# nrf5340_application register map
Vendor: Nordic Semiconductor; Series: nrf53; File version: 1
CPU: CM33 r0p4, little endian, MPU, FPU, 3 interrupt priority bits, 69 interrupts
Registers are 32-bit, read-write, reset 0x0 unless marked. A register's access mark holds for its fields unless they carry their own. Offsets are from the block's base; [hi:lo] are bit positions; {n}, {i} and the like mark numbered series.

## CC_CHACHA_S — CRYPTOCELL CHACHA engine
Base 0x50845000; alternate view of CC_AES_S
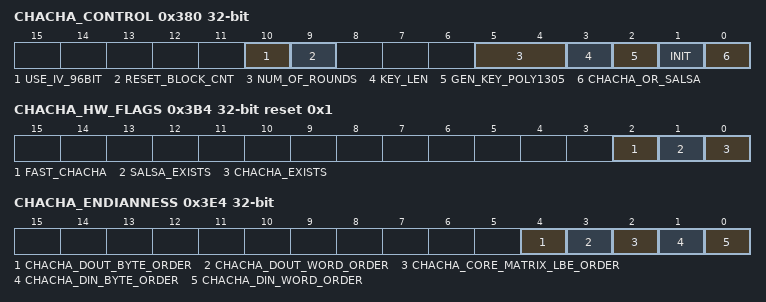
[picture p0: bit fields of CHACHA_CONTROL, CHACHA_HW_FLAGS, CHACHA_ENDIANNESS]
0x380 CHACHA_CONTROL — Control the CHACHA engine behavior.
  [10] USE_IV_96BIT — Use 96 bits Initialization Vector (IV)
    0=Disable (Use default size IV of 64 bit); 1=Enable (The IV is 96 bits)
  [9] RESET_BLOCK_CNT — Reset block counter for new messages
    0=Disable (Use current block counter value); 1=Enable (Reset block counter value to zero)
  [5:4] NUM_OF_ROUNDS — Set number of permutation rounds, default value is 20.
    0=Default (Use 20 rounds of rotation (default)); 1=12Rounds (Use 12 rounds of rotation); 2=8Rounds (Use 8 rounds of rotation)
  [3] KEY_LEN — Key length selection.
    0=256Bits (Use 256 bits key length); 1=128Bits (Use 128 bits key length)
  [2] GEN_KEY_POLY1305 — Generate the key to use in Poly1305 message authentication code calculation.
    0=Disable (Do not generate Poly1305 key); 1=Enable (Generate Poly1305 key)
  [1] INIT — Perform initialization for a new message
    0=Disable (Message already initialized); 1=Enable (Initialize new message)
  [0] CHACHA_OR_SALSA — Run engine in ChaCha or Salsa mode
    0=ChaCha (Run engine in ChaCha mode); 1=Salsa (Run engine in Salsa mode)
0x384 CHACHA_VERSION ro reset 0x1 — CHACHA engine HW version
{0x388+4i} CHACHA_KEY[{i}] (i=0..7) wo — Description collection: CHACHA key value to use. The initial CHACHA_KEY[0] register holds the least significant bits [31:0] of the key value.
  [31:0] VALUE — CHACHA key value.
{0x3A8+4i} CHACHA_IV[{i}] (i=0..1) — Description collection: CHACHA Initialization Vector (IV) to use. The IV is also known as the nonce.
  [31:0] VALUE — CHACHA IV value.
0x3B0 CHACHA_BUSY ro — Status register for CHACHA engine activity.
  [0] STATUS — CHACHA engine status.
    0=Idle (CHACHA engine is idle); 1=Busy (CHACHA engine is busy)
0x3B4 CHACHA_HW_FLAGS ro reset 0x1 — Hardware configuration of the CHACHA engine. Reset value holds the supported features.
  [2] FAST_CHACHA — If this flag is set, the next matrix calculated when the current one is written to data output path.
  [1] SALSA_EXISTS — If this flag is set, the engine include Salsa support
  [0] CHACHA_EXISTS — If this flag is set, the engine include ChaCha support
0x3B8 CHACHA_BLOCK_CNT_LSB — Store the LSB value of the block counter, in order to support suspend/resume of operation
  [31:0] VALUE — This register holds the ChaCha block counter bits [31:0] and must be read and written during respectively suspend and resume operations.
0x3BC CHACHA_BLOCK_CNT_MSB — Store the MSB value of the block counter, in order to support suspend/resume of operation
  [31:0] VALUE — This register holds the ChaCha block counter bits [63:32] and must be read and written during respectively suspend and resume operations.
0x3C0 CHACHA_SW_RESET wo — Reset the CHACHA engine.
  [0] RESET — Writing any value to this address resets the CHACHA engine. The reset takes 4 CPU clock cycles to complete.
    1=Enable (Reset CHACHA engine.)
{0x3C4+4i} CHACHA_POLY1305_KEY[{i}] (i=0..7) ro — Description collection: The auto-generated key to use in Poly1305 MAC calculation. The initial CHACHA_POLY1305_KEY[0] register holds the least significant bits [31:0] of the key value.
  [31:0] VALUE — Poly1305 key value.
0x3E4 CHACHA_ENDIANNESS — CHACHA engine data order configuration.
  [4] CHACHA_DOUT_BYTE_ORDER — Change the byte order of the output data.
    0=Default (Use default byte order within each output word, where bytes are ordered as follows: B0, B1, B2, B3.); 1=Reverse the byte order within each output word, where bytes are re-ordered as follows: B3, B2, B1, B0
  [3] CHACHA_DOUT_WORD_ORDER — Change the word order of the output data.
    0=Default (Uses default word order for 128-bits output, where words are ordered as follows: w0, w1, w2, w3.); 1=Reverse the word order for 128-bits output, where words are re-ordered as follows: w3, w2, w1, w0
  [2] CHACHA_CORE_MATRIX_LBE_ORDER — Change the quarter of a matrix order in the engine.
    0=Default (Use default quarter of matrix order, where quarters are ordered as follows: q0, q1, q2, q3. Each quarter represents a 128-bits section of the matrix.); 1=Reverse the order of matrix quarters, where quarters are re-ordered as follows: q3, q2, q1, q0. Each quarter represents a 128-bits section of the matrix.
  [1] CHACHA_DIN_BYTE_ORDER — Change the byte order of the input data.
    0=Default (Use default byte order within each input word, where bytes are ordered as follows: B0, B1, B2, B3.); 1=Reverse the byte order within each input word, where bytes are re-ordered as follows: B3, B2, B1, B0
  [0] CHACHA_DIN_WORD_ORDER — Change the word order of the input data.
    0=Default (Use default word order for 128-bits input, where words are ordered as follows: w0, w1, w2, w3.); 1=Reverses the word order for 128-bits input, where words are re-ordered as follows: w3, w2, w1, w0
0x3E8 CHACHA_DEBUG ro — Debug register for the CHACHA engine
  [1:0] FSM_STATE — Reflects the debug state of the CHACHA FSM.
    0=IDLE_STATE (CHACHA FSM is in idle state); 1=INIT_STATE (CHACHA FSM is in init state); 2=ROUNDS_STATE (CHACHA FSM is in rounds state); 3=FINAL_STATE (CHACHA FSM is in final state)
